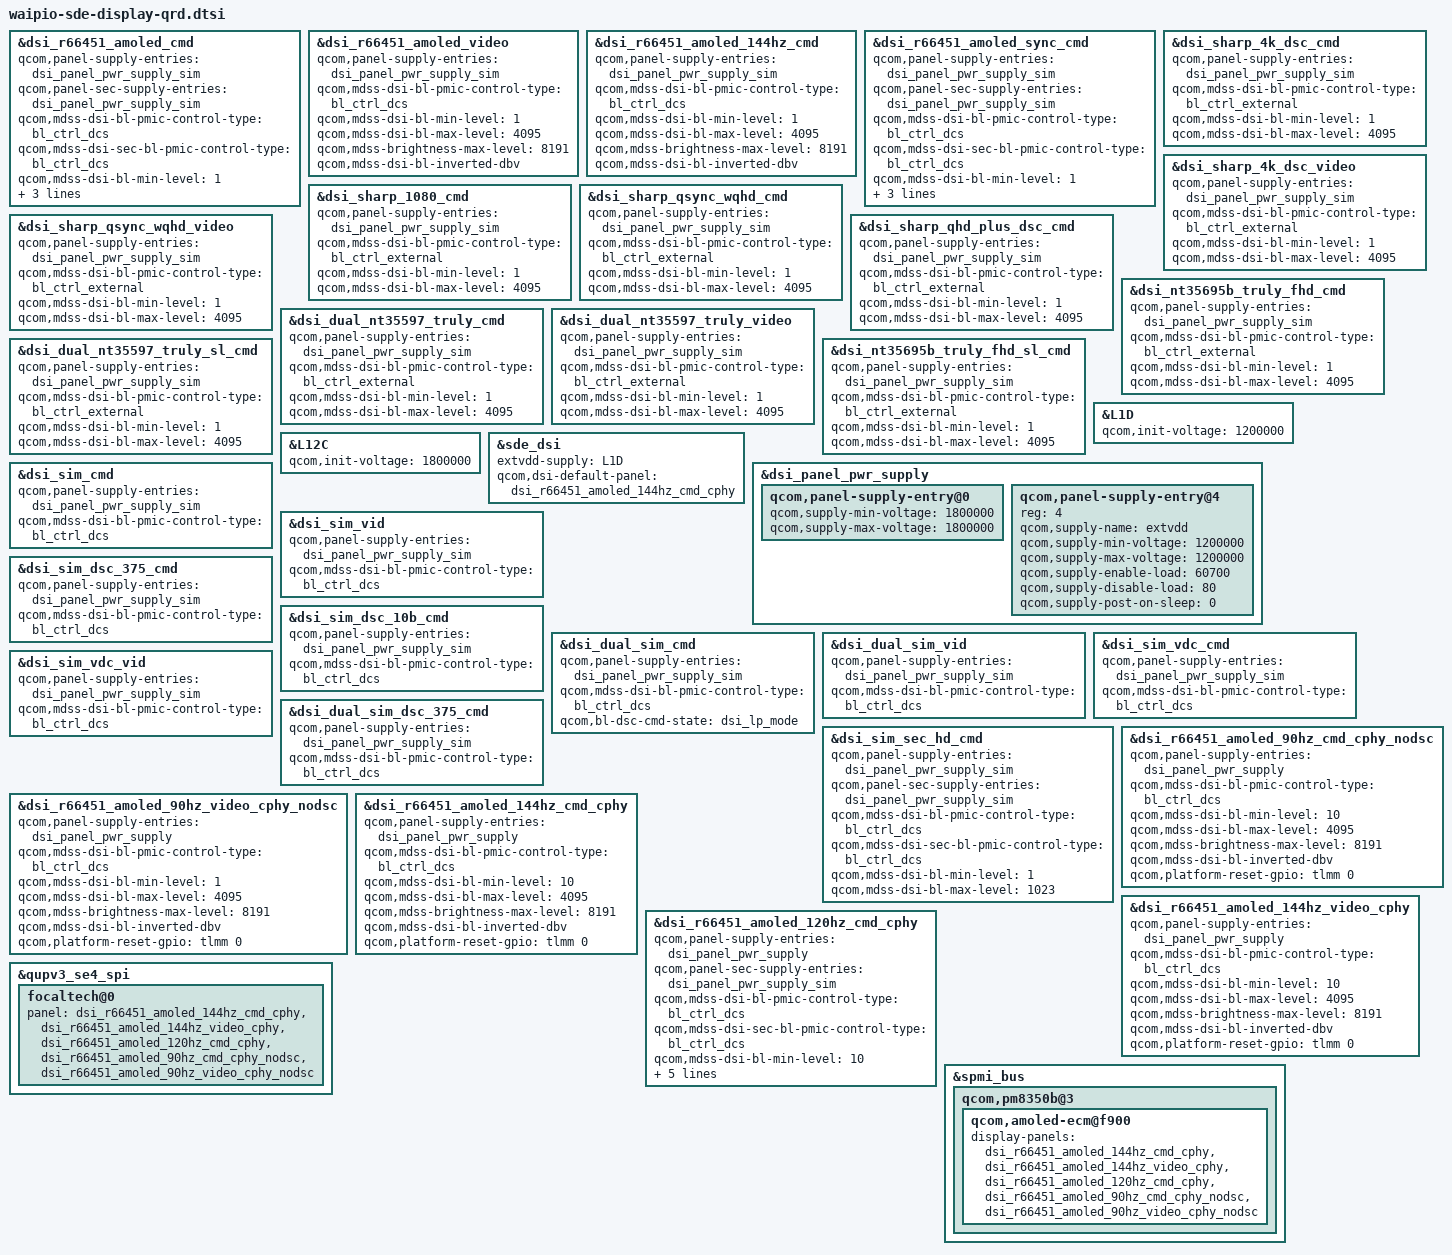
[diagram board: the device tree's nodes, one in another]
#include "waipio-sde-display.dtsi"

&dsi_r66451_amoled_cmd {
	qcom,panel-supply-entries = <&dsi_panel_pwr_supply_sim>;
	qcom,panel-sec-supply-entries = <&dsi_panel_pwr_supply_sim>;
	qcom,mdss-dsi-bl-pmic-control-type = "bl_ctrl_dcs";
	qcom,mdss-dsi-sec-bl-pmic-control-type = "bl_ctrl_dcs";
	qcom,mdss-dsi-bl-min-level = <1>;
	qcom,mdss-dsi-bl-max-level = <4095>;
	qcom,mdss-brightness-max-level = <8191>;
	qcom,mdss-dsi-bl-inverted-dbv;
};

&dsi_r66451_amoled_video {
	qcom,panel-supply-entries = <&dsi_panel_pwr_supply_sim>;
	qcom,mdss-dsi-bl-pmic-control-type = "bl_ctrl_dcs";
	qcom,mdss-dsi-bl-min-level = <1>;
	qcom,mdss-dsi-bl-max-level = <4095>;
	qcom,mdss-brightness-max-level = <8191>;
	qcom,mdss-dsi-bl-inverted-dbv;
};

&dsi_r66451_amoled_144hz_cmd {
	qcom,panel-supply-entries = <&dsi_panel_pwr_supply_sim>;
	qcom,mdss-dsi-bl-pmic-control-type = "bl_ctrl_dcs";
	qcom,mdss-dsi-bl-min-level = <1>;
	qcom,mdss-dsi-bl-max-level = <4095>;
	qcom,mdss-brightness-max-level = <8191>;
	qcom,mdss-dsi-bl-inverted-dbv;
};

&dsi_r66451_amoled_sync_cmd {
	qcom,panel-supply-entries = <&dsi_panel_pwr_supply_sim>;
	qcom,panel-sec-supply-entries = <&dsi_panel_pwr_supply_sim>;
	qcom,mdss-dsi-bl-pmic-control-type = "bl_ctrl_dcs";
	qcom,mdss-dsi-sec-bl-pmic-control-type = "bl_ctrl_dcs";
	qcom,mdss-dsi-bl-min-level = <1>;
	qcom,mdss-dsi-bl-max-level = <4095>;
	qcom,mdss-brightness-max-level = <8191>;
	qcom,mdss-dsi-bl-inverted-dbv;
};

&dsi_sharp_4k_dsc_cmd {
	qcom,panel-supply-entries = <&dsi_panel_pwr_supply_sim>;
	qcom,mdss-dsi-bl-pmic-control-type = "bl_ctrl_external";
	qcom,mdss-dsi-bl-min-level = <1>;
	qcom,mdss-dsi-bl-max-level = <4095>;
};

&dsi_sharp_4k_dsc_video {
	qcom,panel-supply-entries = <&dsi_panel_pwr_supply_sim>;
	qcom,mdss-dsi-bl-pmic-control-type = "bl_ctrl_external";
	qcom,mdss-dsi-bl-min-level = <1>;
	qcom,mdss-dsi-bl-max-level = <4095>;
};

&dsi_sharp_1080_cmd {
	qcom,panel-supply-entries = <&dsi_panel_pwr_supply_sim>;
	qcom,mdss-dsi-bl-pmic-control-type = "bl_ctrl_external";
	qcom,mdss-dsi-bl-min-level = <1>;
	qcom,mdss-dsi-bl-max-level = <4095>;
};

&dsi_sharp_qsync_wqhd_cmd {
	qcom,panel-supply-entries = <&dsi_panel_pwr_supply_sim>;
	qcom,mdss-dsi-bl-pmic-control-type = "bl_ctrl_external";
	qcom,mdss-dsi-bl-min-level = <1>;
	qcom,mdss-dsi-bl-max-level = <4095>;
};

&dsi_sharp_qsync_wqhd_video {
	qcom,panel-supply-entries = <&dsi_panel_pwr_supply_sim>;
	qcom,mdss-dsi-bl-pmic-control-type = "bl_ctrl_external";
	qcom,mdss-dsi-bl-min-level = <1>;
	qcom,mdss-dsi-bl-max-level = <4095>;
};

&dsi_sharp_qhd_plus_dsc_cmd {
	qcom,panel-supply-entries = <&dsi_panel_pwr_supply_sim>;
	qcom,mdss-dsi-bl-pmic-control-type = "bl_ctrl_external";
	qcom,mdss-dsi-bl-min-level = <1>;
	qcom,mdss-dsi-bl-max-level = <4095>;
};

&dsi_nt35695b_truly_fhd_cmd {
	qcom,panel-supply-entries = <&dsi_panel_pwr_supply_sim>;
	qcom,mdss-dsi-bl-pmic-control-type = "bl_ctrl_external";
	qcom,mdss-dsi-bl-min-level = <1>;
	qcom,mdss-dsi-bl-max-level = <4095>;
};

&dsi_dual_nt35597_truly_cmd {
	qcom,panel-supply-entries = <&dsi_panel_pwr_supply_sim>;
	qcom,mdss-dsi-bl-pmic-control-type = "bl_ctrl_external";
	qcom,mdss-dsi-bl-min-level = <1>;
	qcom,mdss-dsi-bl-max-level = <4095>;
};

&dsi_dual_nt35597_truly_video {
	qcom,panel-supply-entries = <&dsi_panel_pwr_supply_sim>;
	qcom,mdss-dsi-bl-pmic-control-type = "bl_ctrl_external";
	qcom,mdss-dsi-bl-min-level = <1>;
	qcom,mdss-dsi-bl-max-level = <4095>;
};

&dsi_dual_nt35597_truly_sl_cmd {
	qcom,panel-supply-entries = <&dsi_panel_pwr_supply_sim>;
	qcom,mdss-dsi-bl-pmic-control-type = "bl_ctrl_external";
	qcom,mdss-dsi-bl-min-level = <1>;
	qcom,mdss-dsi-bl-max-level = <4095>;
};

&dsi_nt35695b_truly_fhd_sl_cmd {
	qcom,panel-supply-entries = <&dsi_panel_pwr_supply_sim>;
	qcom,mdss-dsi-bl-pmic-control-type = "bl_ctrl_external";
	qcom,mdss-dsi-bl-min-level = <1>;
	qcom,mdss-dsi-bl-max-level = <4095>;
};

&L1D {
	qcom,init-voltage = <1200000>; /* panel ext vdd */
};

&L12C {
	qcom,init-voltage = <1800000>; /* panel vddio */
};

&sde_dsi {
	extvdd-supply = <&L1D>;
	qcom,dsi-default-panel = <&dsi_r66451_amoled_144hz_cmd_cphy>;
};

&dsi_panel_pwr_supply {
	qcom,panel-supply-entry@0 {
		qcom,supply-min-voltage = <1800000>;
		qcom,supply-max-voltage = <1800000>;
	};

	qcom,panel-supply-entry@4 {
		reg = <4>;
		qcom,supply-name = "extvdd";
		qcom,supply-min-voltage = <1200000>;
		qcom,supply-max-voltage = <1200000>;
		qcom,supply-enable-load = <60700>;
		qcom,supply-disable-load = <80>;
		qcom,supply-post-on-sleep = <0>;
	};
};

&dsi_sim_cmd {
	qcom,panel-supply-entries = <&dsi_panel_pwr_supply_sim>;
	qcom,mdss-dsi-bl-pmic-control-type = "bl_ctrl_dcs";
};

&dsi_sim_vid {
	qcom,panel-supply-entries = <&dsi_panel_pwr_supply_sim>;
	qcom,mdss-dsi-bl-pmic-control-type = "bl_ctrl_dcs";
};

&dsi_sim_dsc_375_cmd {
	qcom,panel-supply-entries = <&dsi_panel_pwr_supply_sim>;
	qcom,mdss-dsi-bl-pmic-control-type = "bl_ctrl_dcs";
};

&dsi_sim_dsc_10b_cmd {
	qcom,panel-supply-entries = <&dsi_panel_pwr_supply_sim>;
	qcom,mdss-dsi-bl-pmic-control-type = "bl_ctrl_dcs";
};

&dsi_dual_sim_cmd {
	qcom,panel-supply-entries = <&dsi_panel_pwr_supply_sim>;
	qcom,mdss-dsi-bl-pmic-control-type = "bl_ctrl_dcs";
	qcom,bl-dsc-cmd-state = "dsi_lp_mode";
};

&dsi_dual_sim_vid {
	qcom,panel-supply-entries = <&dsi_panel_pwr_supply_sim>;
	qcom,mdss-dsi-bl-pmic-control-type = "bl_ctrl_dcs";
};

&dsi_sim_vdc_cmd {
	qcom,panel-supply-entries = <&dsi_panel_pwr_supply_sim>;
	qcom,mdss-dsi-bl-pmic-control-type = "bl_ctrl_dcs";
};

&dsi_sim_vdc_vid {
	qcom,panel-supply-entries = <&dsi_panel_pwr_supply_sim>;
	qcom,mdss-dsi-bl-pmic-control-type = "bl_ctrl_dcs";
};

&dsi_dual_sim_dsc_375_cmd {
	qcom,panel-supply-entries = <&dsi_panel_pwr_supply_sim>;
	qcom,mdss-dsi-bl-pmic-control-type = "bl_ctrl_dcs";
};

&dsi_sim_sec_hd_cmd {
	qcom,panel-supply-entries = <&dsi_panel_pwr_supply_sim>;
	qcom,panel-sec-supply-entries = <&dsi_panel_pwr_supply_sim>;
	qcom,mdss-dsi-bl-pmic-control-type = "bl_ctrl_dcs";
	qcom,mdss-dsi-sec-bl-pmic-control-type = "bl_ctrl_dcs";
	qcom,mdss-dsi-bl-min-level = <1>;
	qcom,mdss-dsi-bl-max-level = <1023>;
};

&dsi_r66451_amoled_90hz_cmd_cphy_nodsc {
	qcom,panel-supply-entries = <&dsi_panel_pwr_supply>;
	qcom,mdss-dsi-bl-pmic-control-type = "bl_ctrl_dcs";
	qcom,mdss-dsi-bl-min-level = <10>;
	qcom,mdss-dsi-bl-max-level = <4095>;
	qcom,mdss-brightness-max-level = <8191>;
	qcom,mdss-dsi-bl-inverted-dbv;
	qcom,platform-reset-gpio = <&tlmm 0 0>;
};

&dsi_r66451_amoled_90hz_video_cphy_nodsc {
	qcom,panel-supply-entries = <&dsi_panel_pwr_supply>;
	qcom,mdss-dsi-bl-pmic-control-type = "bl_ctrl_dcs";
	qcom,mdss-dsi-bl-min-level = <1>;
	qcom,mdss-dsi-bl-max-level = <4095>;
	qcom,mdss-brightness-max-level = <8191>;
	qcom,mdss-dsi-bl-inverted-dbv;
	qcom,platform-reset-gpio = <&tlmm 0 0>;
};

&dsi_r66451_amoled_144hz_cmd_cphy {
	qcom,panel-supply-entries = <&dsi_panel_pwr_supply>;
	qcom,mdss-dsi-bl-pmic-control-type = "bl_ctrl_dcs";
	qcom,mdss-dsi-bl-min-level = <10>;
	qcom,mdss-dsi-bl-max-level = <4095>;
	qcom,mdss-brightness-max-level = <8191>;
	qcom,mdss-dsi-bl-inverted-dbv;
	qcom,platform-reset-gpio = <&tlmm 0 0>;
};

&dsi_r66451_amoled_144hz_video_cphy {
	qcom,panel-supply-entries = <&dsi_panel_pwr_supply>;
	qcom,mdss-dsi-bl-pmic-control-type = "bl_ctrl_dcs";
	qcom,mdss-dsi-bl-min-level = <10>;
	qcom,mdss-dsi-bl-max-level = <4095>;
	qcom,mdss-brightness-max-level = <8191>;
	qcom,mdss-dsi-bl-inverted-dbv;
	qcom,platform-reset-gpio = <&tlmm 0 0>;
};

&dsi_r66451_amoled_120hz_cmd_cphy {
	qcom,panel-supply-entries = <&dsi_panel_pwr_supply>;
	qcom,panel-sec-supply-entries = <&dsi_panel_pwr_supply_sim>;
	qcom,mdss-dsi-bl-pmic-control-type = "bl_ctrl_dcs";
	qcom,mdss-dsi-sec-bl-pmic-control-type = "bl_ctrl_dcs";
	qcom,mdss-dsi-bl-min-level = <10>;
	qcom,mdss-dsi-bl-max-level = <4095>;
	qcom,mdss-brightness-max-level = <8191>;
	qcom,mdss-dsi-bl-inverted-dbv;
	qcom,platform-reset-gpio = <&tlmm 0 0>;
	qcom,platform-sec-reset-gpio = <&tlmm 4 0>;
};

&qupv3_se4_spi {
	focaltech@0 {
		panel = <&dsi_r66451_amoled_144hz_cmd_cphy
			&dsi_r66451_amoled_144hz_video_cphy
			&dsi_r66451_amoled_120hz_cmd_cphy
			&dsi_r66451_amoled_90hz_cmd_cphy_nodsc
			&dsi_r66451_amoled_90hz_video_cphy_nodsc>;
	};
};

&spmi_bus {
	qcom,pm8350b@3 {
		qcom,amoled-ecm@f900 {
			display-panels = <&dsi_r66451_amoled_144hz_cmd_cphy
				&dsi_r66451_amoled_144hz_video_cphy
				&dsi_r66451_amoled_120hz_cmd_cphy
				&dsi_r66451_amoled_90hz_cmd_cphy_nodsc
				&dsi_r66451_amoled_90hz_video_cphy_nodsc>;
		};
	};
};
